VERSION ""

NS_ :

BS_:
BU_: Motor Controller
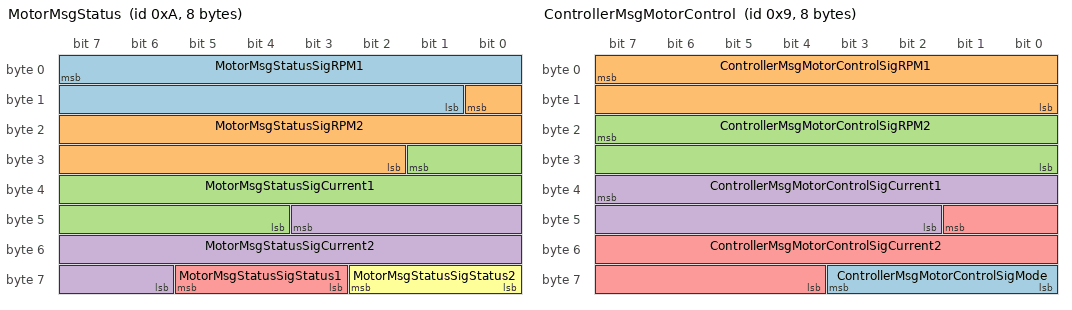
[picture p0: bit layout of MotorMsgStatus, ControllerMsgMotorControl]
BO_ 10 MotorMsgStatus: 8 Motor
   SG_ MotorMsgStatusSigRPM1 : 7|15@0- (1,0) [-15000|15000] "RPM" Controller
   SG_ MotorMsgStatusSigRPM2 : 8|15@0- (1,0) [-15000|15000] "RPM" Controller
   SG_ MotorMsgStatusSigCurrent1 : 25|14@0- (1,0) [-6000|6000] "mA" Controller
   SG_ MotorMsgStatusSigCurrent2 : 43|14@0- (1,0) [-6000|6000] "mA" Controller
   SG_ MotorMsgStatusSigStatus1 : 61|3@0+ (1,0) [0|7] "" Controller
   SG_ MotorMsgStatusSigStatus2 : 58|3@0+ (1,0) [0|7] "" Controller

BO_ 9 ControllerMsgMotorControl: 8 Controller
   SG_ ControllerMsgMotorControlSigMode : 59|4@0+ (1,0) [0|11] "" Motor
   SG_ ControllerMsgMotorControlSigRPM1 : 7|16@0- (1,0) [-15000|15000] "RPM" Motor
   SG_ ControllerMsgMotorControlSigRPM2 : 23|16@0- (1,0) [-15000|15000] "RPM" Motor
   SG_ ControllerMsgMotorControlSigCurrent1 : 39|14@0- (1,0) [-6000|6000] "mA" Motor
   SG_ ControllerMsgMotorControlSigCurrent2 : 41|14@0- (1,0) [-6000|6000] "mA" Motor

BA_DEF_ BO_ "GenMsgBackgroundColor" STRING ;
BA_DEF_ BO_ "GenMsgForegroundColor" STRING ;
BA_DEF_ BO_ "filterlabeling" INT 0 0;
BA_DEF_ BO_ "filterlabeling" INT 0 0;
BA_DEF_ BO_ "filterlabeling" INT 0 0;
BA_ "GenMsgForegroundColor" BO_ 10 "#ef2929";
BA_ "GenMsgForegroundColor" BO_ 9 "#ef2929";
BA_DEF_DEF_ "GenMsgBackgroundColor" "#ffffff";
BA_DEF_DEF_ "GenMsgForegroundColor" "#000000";
BA_DEF_DEF_ "filterlabeling" 1;
VAL_ 10 MotorMsgStatusSigCurrent2 0 "No Description";
